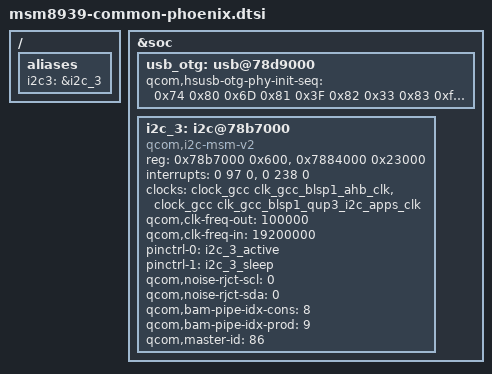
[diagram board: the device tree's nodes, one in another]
/* Copyright (c) 2020, The Linux Foundation. All rights reserved.
 *
 * This program is free software; you can redistribute it and/or modify
 * it under the terms of the GNU General Public License version 2 and
 * only version 2 as published by the Free Software Foundation.
 *
 * This program is distributed in the hope that it will be useful,
 * but WITHOUT ANY WARRANTY; without even the implied warranty of
 * MERCHANTABILITY or FITNESS FOR A PARTICULAR PURPOSE.  See the
 * GNU General Public License for more details.
 */

/ {
	aliases {
		i2c3 = &i2c_3;
		/delete-property/ spi0;
	};
};

&soc {
	usb_otg: usb@78d9000 {
		/delete-property/ qcom,hsusb-otg-phy-init-seq;
		qcom,hsusb-otg-phy-init-seq =
			<0x74 0x80 0x6D 0x81 0x3F 0x82 0x33 0x83 0xffffffff>;
	};

	/delete-node/ spi@78b7000;

	i2c_3: i2c@78b7000 { /* BLSP1 QUP2 */
		compatible = "qcom,i2c-msm-v2";
		#address-cells = <1>;
		#size-cells = <0>;
		reg-names = "qup_phys_addr", "bam_phys_addr";
		reg = <0x78b7000 0x600>,
		      <0x7884000 0x23000>;
		interrupt-names = "qup_irq", "bam_irq";
		interrupts = <0 97 0>, <0 238 0>;
		clocks = <&clock_gcc clk_gcc_blsp1_ahb_clk>,
			 <&clock_gcc clk_gcc_blsp1_qup3_i2c_apps_clk>;
		clock-names = "iface_clk", "core_clk";
		qcom,clk-freq-out = <100000>;
		qcom,clk-freq-in  = <19200000>;
		pinctrl-names = "i2c_active", "i2c_sleep";
		pinctrl-0 = <&i2c_3_active>;
		pinctrl-1 = <&i2c_3_sleep>;
		qcom,noise-rjct-scl = <0>;
		qcom,noise-rjct-sda = <0>;
		qcom,bam-pipe-idx-cons = <8>;
		qcom,bam-pipe-idx-prod = <9>;
		qcom,master-id = <86>;
	};
};
